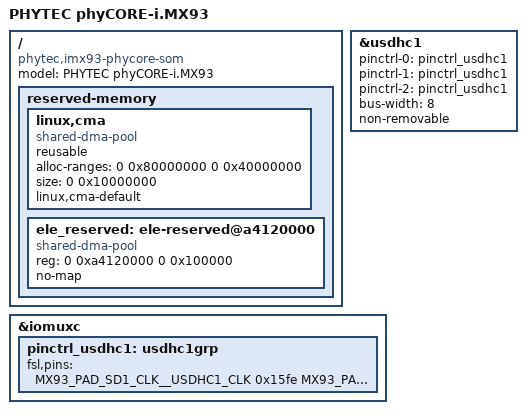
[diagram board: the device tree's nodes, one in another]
// SPDX-License-Identifier: (GPL-2.0+ OR MIT)
/*
 * Copyright (C) 2023 PHYTEC Messtechnik GmbH
 * Christoph Stoidner <c.stoidner@phytec.de>
 * Copyright (C) 2024 Mathieu Othacehe <m.othacehe@gmail.com>
 *
 */
/dts-v1/;

#include "imx93.dtsi"

/{
	model = "PHYTEC phyCORE-i.MX93";
	compatible = "phytec,imx93-phycore-som", "fsl,imx93";

	reserved-memory {
		ranges;
		#address-cells = <2>;
		#size-cells = <2>;

		linux,cma {
			compatible = "shared-dma-pool";
			reusable;
			alloc-ranges = <0 0x80000000 0 0x40000000>;
			size = <0 0x10000000>;
			linux,cma-default;
		};

		ele_reserved: ele-reserved@a4120000 {
			compatible = "shared-dma-pool";
			reg = <0 0xa4120000 0 0x100000>;
			no-map;
		};
	};
};

/* eMMC */
&usdhc1 {
	pinctrl-names = "default", "state_100mhz", "state_200mhz";
	pinctrl-0 = <&pinctrl_usdhc1>;
	pinctrl-1 = <&pinctrl_usdhc1>;
	pinctrl-2 = <&pinctrl_usdhc1>;
	bus-width = <8>;
	non-removable;
	status = "okay";
};

&iomuxc {
	pinctrl_usdhc1: usdhc1grp {
		fsl,pins = <
			MX93_PAD_SD1_CLK__USDHC1_CLK		0x15fe
			MX93_PAD_SD1_CMD__USDHC1_CMD		0x13fe
			MX93_PAD_SD1_DATA0__USDHC1_DATA0	0x13fe
			MX93_PAD_SD1_DATA1__USDHC1_DATA1	0x13fe
			MX93_PAD_SD1_DATA2__USDHC1_DATA2	0x13fe
			MX93_PAD_SD1_DATA3__USDHC1_DATA3	0x13fe
			MX93_PAD_SD1_DATA4__USDHC1_DATA4	0x13fe
			MX93_PAD_SD1_DATA5__USDHC1_DATA5	0x13fe
			MX93_PAD_SD1_DATA6__USDHC1_DATA6	0x13fe
			MX93_PAD_SD1_DATA7__USDHC1_DATA7	0x13fe
			MX93_PAD_SD1_STROBE__USDHC1_STROBE	0x15fe
		>;
	};
};
